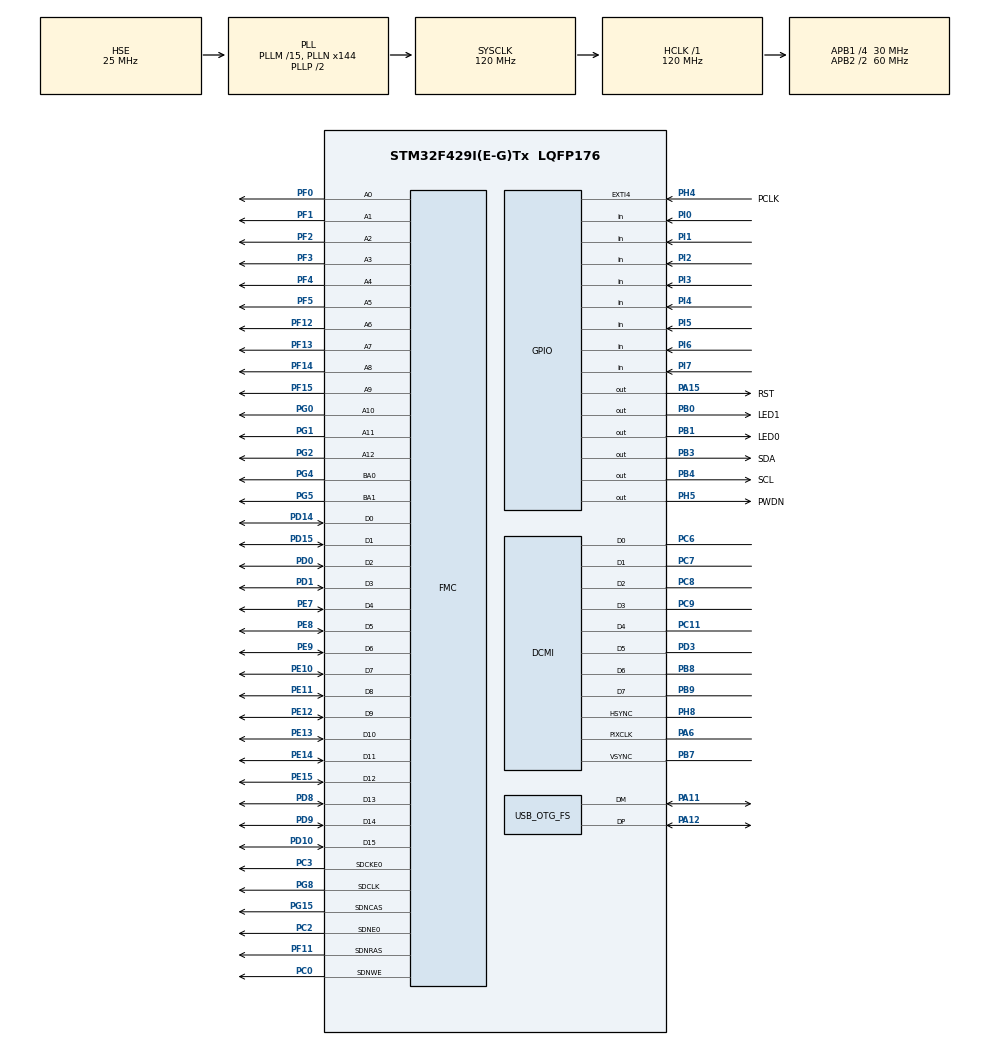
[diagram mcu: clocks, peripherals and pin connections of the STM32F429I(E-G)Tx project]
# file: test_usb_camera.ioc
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DCMI.PCKPolarity=DCMI_PCKPOLARITY_RISING
Dma.DCMI.0.Direction=DMA_PERIPH_TO_MEMORY
Dma.DCMI.0.FIFOMode=DMA_FIFOMODE_ENABLE
Dma.DCMI.0.FIFOThreshold=DMA_FIFO_THRESHOLD_HALFFULL
Dma.DCMI.0.Instance=DMA2_Stream1
Dma.DCMI.0.MemBurst=DMA_MBURST_SINGLE
Dma.DCMI.0.MemDataAlignment=DMA_MDATAALIGN_WORD
Dma.DCMI.0.MemInc=DMA_MINC_ENABLE
Dma.DCMI.0.Mode=DMA_CIRCULAR
Dma.DCMI.0.PeriphBurst=DMA_PBURST_SINGLE
Dma.DCMI.0.PeriphDataAlignment=DMA_PDATAALIGN_WORD
Dma.DCMI.0.PeriphInc=DMA_PINC_DISABLE
Dma.DCMI.0.Priority=DMA_PRIORITY_HIGH
Dma.Request0=DCMI
FMC.CASLatency1=FMC_SDRAM_CAS_LATENCY_3
FMC.ColumnBitsNumber1=FMC_SDRAM_COLUMN_BITS_NUM_9
FMC.ExitSelfRefreshDelay1=8
FMC.LoadToActiveDelay1=2
FMC.RCDDelay1=2
FMC.RPDelay1=2
FMC.RPDelay2=2
FMC.ReadBurst1=FMC_SDRAM_RBURST_ENABLE
FMC.ReadBurst2=FMC_SDRAM_RBURST_ENABLE
FMC.ReadPipeDelay1=FMC_SDRAM_RPIPE_DELAY_1
FMC.ReadPipeDelay2=FMC_SDRAM_RPIPE_DELAY_1
FMC.RowCycleDelay1=6
FMC.RowCycleDelay2=6
FMC.SDClockPeriod1=FMC_SDRAM_CLOCK_PERIOD_2
FMC.SDClockPeriod2=FMC_SDRAM_CLOCK_PERIOD_2
FMC.SelfRefreshTime1=6
FMC.WriteRecoveryTime1=4
Mcu.Family=STM32F4
Mcu.Name=STM32F429I(E-G)Tx
Mcu.Package=LQFP176
NVIC.DCMI_IRQn=true\:0\:0\:false\:false\:true\:true\:true
NVIC.DMA2_Stream1_IRQn=true\:0\:0\:false\:false\:true\:false\:true
NVIC.EXTI4_IRQn=true\:0\:0\:false\:false\:true\:true\:true
NVIC.OTG_FS_IRQn=true\:0\:0\:false\:false\:true\:false\:true
NVIC.PriorityGroup=NVIC_PRIORITYGROUP_4
PA11.Mode=Device_Only
PA11.Signal=USB_OTG_FS_DM
PA12.Mode=Device_Only
PA12.Signal=USB_OTG_FS_DP
PA15.GPIO_Label=RST
PA15.GPIO_PuPd=GPIO_PULLUP
PA15.GPIO_Speed=GPIO_SPEED_FREQ_VERY_HIGH
PA15.Signal=GPIO_Output
PA6.GPIO_PuPd=GPIO_PULLUP
PA6.GPIO_Speed=GPIO_SPEED_FREQ_VERY_HIGH
PA6.Mode=Slave_8_bits_External_Synchro
PA6.Signal=DCMI_PIXCLK
PB0.GPIO_Label=LED1
PB0.GPIO_PuPd=GPIO_PULLUP
PB0.GPIO_Speed=GPIO_SPEED_FREQ_VERY_HIGH
PB0.PinState=GPIO_PIN_SET
PB0.Signal=GPIO_Output
PB1.GPIO_Label=LED0
PB1.GPIO_PuPd=GPIO_PULLUP
PB1.GPIO_Speed=GPIO_SPEED_FREQ_VERY_HIGH
PB1.PinState=GPIO_PIN_SET
PB1.Signal=GPIO_Output
PB3.GPIO_Label=SDA
PB3.GPIO_ModeDefaultOutputPP=GPIO_MODE_OUTPUT_PP
PB3.GPIO_PuPd=GPIO_PULLUP
PB3.GPIO_Speed=GPIO_SPEED_FREQ_HIGH
PB3.Signal=GPIO_Output
PB4.GPIO_Label=SCL
PB4.GPIO_ModeDefaultOutputPP=GPIO_MODE_OUTPUT_PP
PB4.GPIO_PuPd=GPIO_PULLUP
PB4.GPIO_Speed=GPIO_SPEED_FREQ_HIGH
PB4.Signal=GPIO_Output
PB7.GPIO_PuPd=GPIO_PULLUP
PB7.GPIO_Speed=GPIO_SPEED_FREQ_VERY_HIGH
PB7.Mode=Slave_8_bits_External_Synchro
PB7.Signal=DCMI_VSYNC
PB8.GPIO_PuPd=GPIO_PULLUP
PB8.GPIO_Speed=GPIO_SPEED_FREQ_VERY_HIGH
PB8.Mode=Slave_8_bits_External_Synchro
PB8.Signal=DCMI_D6
PB9.GPIO_PuPd=GPIO_PULLUP
PB9.GPIO_Speed=GPIO_SPEED_FREQ_VERY_HIGH
PB9.Mode=Slave_8_bits_External_Synchro
PB9.Signal=DCMI_D7
PC0.Signal=FMC_SDNWE
PC11.GPIO_PuPd=GPIO_PULLUP
PC11.GPIO_Speed=GPIO_SPEED_FREQ_VERY_HIGH
PC11.Mode=Slave_8_bits_External_Synchro
PC11.Signal=DCMI_D4
PC2.Mode=SdramChipSelect1_1
PC2.Signal=FMC_SDNE0
PC3.Mode=SdramChipSelect1_1
PC3.Signal=FMC_SDCKE0
PC6.GPIO_PuPd=GPIO_PULLUP
PC6.GPIO_Speed=GPIO_SPEED_FREQ_VERY_HIGH
PC6.Mode=Slave_8_bits_External_Synchro
PC6.Signal=DCMI_D0
PC7.GPIO_PuPd=GPIO_PULLUP
PC7.GPIO_Speed=GPIO_SPEED_FREQ_VERY_HIGH
PC7.Mode=Slave_8_bits_External_Synchro
PC7.Signal=DCMI_D1
PC8.GPIO_PuPd=GPIO_PULLUP
PC8.GPIO_Speed=GPIO_SPEED_FREQ_VERY_HIGH
PC8.Mode=Slave_8_bits_External_Synchro
PC8.Signal=DCMI_D2
PC9.GPIO_PuPd=GPIO_PULLUP
PC9.GPIO_Speed=GPIO_SPEED_FREQ_VERY_HIGH
PC9.Mode=Slave_8_bits_External_Synchro
PC9.Signal=DCMI_D3
PD0.Signal=FMC_D2_DA2
PD1.Signal=FMC_D3_DA3
PD10.Signal=FMC_D15_DA15
PD14.Signal=FMC_D0_DA0
PD15.Signal=FMC_D1_DA1
PD3.GPIO_PuPd=GPIO_PULLUP
PD3.GPIO_Speed=GPIO_SPEED_FREQ_VERY_HIGH
PD3.Mode=Slave_8_bits_External_Synchro
PD3.Signal=DCMI_D5
PD8.Signal=FMC_D13_DA13
PD9.Signal=FMC_D14_DA14
PE10.Signal=FMC_D7_DA7
PE11.Signal=FMC_D8_DA8
PE12.Signal=FMC_D9_DA9
PE13.Signal=FMC_D10_DA10
PE14.Signal=FMC_D11_DA11
PE15.Signal=FMC_D12_DA12
PE7.Signal=FMC_D4_DA4
PE8.Signal=FMC_D5_DA5
PE9.Signal=FMC_D6_DA6
PF0.Signal=FMC_A0
PF1.Signal=FMC_A1
PF11.Signal=FMC_SDNRAS
PF12.Signal=FMC_A6
PF13.Signal=FMC_A7
PF14.Signal=FMC_A8
PF15.Signal=FMC_A9
PF2.Signal=FMC_A2
PF3.Signal=FMC_A3
PF4.Signal=FMC_A4
PF5.Signal=FMC_A5
PG0.Signal=FMC_A10
PG1.Signal=FMC_A11
PG15.Signal=FMC_SDNCAS
PG2.Signal=FMC_A12
PG4.Signal=FMC_A14_BA0
PG5.Signal=FMC_A15_BA1
PG8.Signal=FMC_SDCLK
PH0/OSC_IN.Mode=HSE-External-Oscillator
PH0/OSC_IN.Signal=RCC_OSC_IN
PH1/OSC_OUT.Mode=HSE-External-Oscillator
PH1/OSC_OUT.Signal=RCC_OSC_OUT
PH4.GPIO_Label=PCLK
PH4.GPIO_ModeDefaultEXTI=GPIO_MODE_IT_RISING
PH4.GPIO_PuPd=GPIO_PULLUP
PH4.Signal=GPXTI4
PH5.GPIO_Label=PWDN
PH5.GPIO_PuPd=GPIO_PULLUP
PH5.GPIO_Speed=GPIO_SPEED_FREQ_VERY_HIGH
PH5.Signal=GPIO_Output
PH8.GPIO_PuPd=GPIO_PULLUP
PH8.GPIO_Speed=GPIO_SPEED_FREQ_VERY_HIGH
PH8.Mode=Slave_8_bits_External_Synchro
PH8.Signal=DCMI_HSYNC
PI0.GPIO_PuPd=GPIO_PULLUP
PI0.Signal=GPIO_Input
PI1.GPIO_PuPd=GPIO_PULLUP
PI1.Signal=GPIO_Input
PI2.GPIO_PuPd=GPIO_PULLUP
PI2.Signal=GPIO_Input
PI3.GPIO_PuPd=GPIO_PULLUP
PI3.Signal=GPIO_Input
PI4.GPIO_PuPd=GPIO_PULLUP
PI4.Signal=GPIO_Input
PI5.GPIO_PuPd=GPIO_PULLUP
PI5.Signal=GPIO_Input
PI6.GPIO_PuPd=GPIO_PULLUP
PI6.Signal=GPIO_Input
PI7.GPIO_PuPd=GPIO_PULLUP
PI7.Signal=GPIO_Input
ProjectManager.HeapSize=0x600
ProjectManager.StackSize=0x400
ProjectManager.TargetToolchain=MDK-ARM V5
RCC.48MHZClocksFreq_Value=48000000
RCC.AHBFreq_Value=120000000
RCC.APB1CLKDivider=RCC_HCLK_DIV4
RCC.APB1Freq_Value=30000000
RCC.APB1TimFreq_Value=60000000
RCC.APB2CLKDivider=RCC_HCLK_DIV2
RCC.APB2Freq_Value=60000000
RCC.APB2TimFreq_Value=120000000
RCC.CortexFreq_Value=120000000
RCC.HCLKFreq_Value=120000000
RCC.HSE_VALUE=25000000
RCC.HSI_VALUE=16000000
RCC.LSE_VALUE=32768
RCC.PLLM=15
RCC.PLLN=144
RCC.PLLQ=5
RCC.SYSCLKFreq_VALUE=120000000
RCC.SYSCLKSource=RCC_SYSCLKSOURCE_PLLCLK
RCC.VCOOutputFreq_Value=240000000
SH.FMC_A0.0=FMC_A0,13b-sda1
SH.FMC_A1.0=FMC_A1,13b-sda1
SH.FMC_A10.0=FMC_A10,13b-sda1
SH.FMC_A11.0=FMC_A11,13b-sda1
SH.FMC_A12.0=FMC_A12,13b-sda1
SH.FMC_A14_BA0.0=FMC_BA0,FourSdramBanks1
SH.FMC_A15_BA1.0=FMC_BA1,FourSdramBanks1
SH.FMC_A2.0=FMC_A2,13b-sda1
SH.FMC_A3.0=FMC_A3,13b-sda1
SH.FMC_A4.0=FMC_A4,13b-sda1
SH.FMC_A5.0=FMC_A5,13b-sda1
SH.FMC_A6.0=FMC_A6,13b-sda1
SH.FMC_A7.0=FMC_A7,13b-sda1
SH.FMC_A8.0=FMC_A8,13b-sda1
SH.FMC_A9.0=FMC_A9,13b-sda1
SH.FMC_D0_DA0.0=FMC_D0,sd-16b-d1
SH.FMC_D10_DA10.0=FMC_D10,sd-16b-d1
SH.FMC_D11_DA11.0=FMC_D11,sd-16b-d1
SH.FMC_D12_DA12.0=FMC_D12,sd-16b-d1
SH.FMC_D13_DA13.0=FMC_D13,sd-16b-d1
SH.FMC_D14_DA14.0=FMC_D14,sd-16b-d1
SH.FMC_D15_DA15.0=FMC_D15,sd-16b-d1
SH.FMC_D1_DA1.0=FMC_D1,sd-16b-d1
SH.FMC_D2_DA2.0=FMC_D2,sd-16b-d1
SH.FMC_D3_DA3.0=FMC_D3,sd-16b-d1
SH.FMC_D4_DA4.0=FMC_D4,sd-16b-d1
SH.FMC_D5_DA5.0=FMC_D5,sd-16b-d1
SH.FMC_D6_DA6.0=FMC_D6,sd-16b-d1
SH.FMC_D7_DA7.0=FMC_D7,sd-16b-d1
SH.FMC_D8_DA8.0=FMC_D8,sd-16b-d1
SH.FMC_D9_DA9.0=FMC_D9,sd-16b-d1
SH.FMC_SDCLK.0=FMC_SDCLK,13b-sda1
SH.FMC_SDNCAS.0=FMC_SDNCAS,13b-sda1
SH.FMC_SDNRAS.0=FMC_SDNRAS,13b-sda1
SH.FMC_SDNWE.0=FMC_SDNWE,13b-sda1
USB_DEVICE.CLASS_NAME_FS=CDC
USB_DEVICE.VirtualMode-CDC_FS=Cdc
USB_DEVICE.VirtualModeFS=Cdc_FS
USB_OTG_FS.VirtualMode=Device_Only
VP_USB_DEVICE_VS_USB_DEVICE_CDC_FS.Mode=CDC_FS
board=custom

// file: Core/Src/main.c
/* USER CODE BEGIN Header */
/**
  ******************************************************************************
  * @file           : main.c
  * @brief          : Main program body
  ******************************************************************************
  * @attention
  *
  * <h2><center>&copy; Copyright (c) 2021 STMicroelectronics.
  * All rights reserved.</center></h2>
  *
  * This software component is licensed by ST under Ultimate Liberty license
  * SLA0044, the "License"; You may not use this file except in compliance with
  * the License. You may obtain a copy of the License at:
  *                             www.st.com/SLA0044
  *
  ******************************************************************************
  */
/* USER CODE END Header */
#include "main.h"
#include "dcmi.h"
#include "dma.h"
#include "usb_device.h"
#include "gpio.h"
#include "fmc.h"

/* USER CODE BEGIN Includes */
#include "usbd_cdc_if.h"
#include "hardware.h"
//#include "sdram.h"
#include "usb_app.h"
/* USER CODE END Includes */

void SystemClock_Config(void);

/* USER CODE BEGIN 0 */

#define BUFFER_SIZE 2*1024
#define DATA_SIZE 30*1024

uint32_t jpeg_data[DATA_SIZE]__attribute__((at(0XC0000000+1280*800*2)));
uint32_t jpeg_buffer[2][BUFFER_SIZE];
uint32_t jpeg_data_len = 0;
uint8_t jpeg_process_state = 0;
uint8_t current_buffer = 0;
uint8_t buf[4];

void save_buffer(uint8_t buffer_num)
{
	uint32_t *p = jpeg_data + jpeg_data_len;
	for(uint32_t i=0; i<BUFFER_SIZE; i++)
	{
		p[i] = jpeg_buffer[buffer_num][i];
	}
	jpeg_data_len = jpeg_data_len+BUFFER_SIZE;
}

void data_process()
{
	if(jpeg_process_state == 0)
	{
		save_buffer(current_buffer);
		jpeg_process_state = 1;
	}
	else if(jpeg_process_state == 2)
	{
		jpeg_process_state = 0;
		jpeg_data_len = 0;
	}
}

//void HAL_TIM_IC_CaptureCallback(TIM_HandleTypeDef *htim)
//{
//	if(jpeg_process_state == 0)
//	{
//		save_buffer(1);
//	}
//	current_buffer = 0;
//}

//void HAL_TIM_IC_CaptureHalfCpltCallback(TIM_HandleTypeDef *htim)
//{
//	if(jpeg_process_state == 0)
//	{
//		save_buffer(0);
//	}
//	current_buffer = 1;
//}

//void HAL_GPIO_EXTI_Callback(uint16_t GPIO_Pin)
//{
//	if(GPIO_Pin == GPIO_PIN_4)
//	{
//		if(jpeg_process_state)
//		{
//			jpeg_data[jpeg_data_len++] = GPIOI->IDR;
//		}
//	}
//	else if(GPIO_Pin == GPIO_PIN_7)
//	{
//		data_process();
//	}
//}

void HAL_DCMI_VsyncEventCallback(DCMI_HandleTypeDef *hdcmi)
{
	data_process();//jpeg数据处理
  __HAL_DCMI_ENABLE_IT(hdcmi, DCMI_FLAG_VSYNCRI);
}

void DCMI_DMAXferCplt(DMA_HandleTypeDef *hdma)
{
	if(jpeg_process_state==0)
	{
		HW_LED_turn(&led0);
		save_buffer(0);
	}
	current_buffer = 1;
}

void DCMI_DMAXferM1Cplt(DMA_HandleTypeDef *hdma)
{
	if(jpeg_process_state==0)
	{
		HW_LED_turn(&led1);
		save_buffer(1);
	}
	current_buffer = 0;
}

void DCMI_DMAXferError(DMA_HandleTypeDef *hdma)
{
	UNUSED(hdma);
}

HAL_StatusTypeDef dcmi_start(DCMI_HandleTypeDef* hdcmi, uint32_t DCMI_Mode, uint32_t pData, uint32_t pData2, uint32_t Length)
{
  /* Process Locked */
  __HAL_LOCK(hdcmi);

  /* Lock the DCMI peripheral state */
  hdcmi->State = HAL_DCMI_STATE_BUSY;

  /* Enable DCMI by setting DCMIEN bit */
  __HAL_DCMI_ENABLE(hdcmi);

  /* Configure the DCMI Mode */
  hdcmi->Instance->CR &= ~(DCMI_CR_CM);
  hdcmi->Instance->CR |=  (uint32_t)(DCMI_Mode);

  hdcmi->XferCount = 0U;
  hdcmi->XferTransferNumber = 0U;

//	__HAL_UNLOCK(&hdma_dcmi);
	hdcmi->DMA_Handle->XferCpltCallback = DCMI_DMAXferCplt;
	hdcmi->DMA_Handle->XferM1CpltCallback = DCMI_DMAXferM1Cplt;
	hdcmi->DMA_Handle->XferErrorCallback = DCMI_DMAXferError;
	HAL_DMAEx_MultiBufferStart_IT(hdcmi->DMA_Handle, (uint32_t)&hdcmi->Instance->DR, (uint32_t)pData, (uint32_t)pData2, Length);

  /* Enable Capture */
  hdcmi->Instance->CR |= DCMI_CR_CAPTURE;

  /* Release Lock */
  __HAL_UNLOCK(hdcmi);
  return HAL_OK;
}

/* USER CODE END 0 */

int main(void)
{

  /* MCU Configuration--------------------------------------------------------*/

  /* Reset of all peripherals, Initializes the Flash interface and the Systick. */
  HAL_Init();

  /* Configure the system clock */
  SystemClock_Config();

  /* Initialize all configured peripherals */
  MX_GPIO_Init();
  MX_DMA_Init();
  MX_USB_DEVICE_Init();
  MX_DCMI_Init();
  MX_FMC_Init();
  /* USER CODE BEGIN 2 */

	// sdram
//	SDRAM_Init();

	// led
	led_init();
	HW_LED_set(&led0, HW_LED_OFF);
	HW_LED_set(&led1, HW_LED_OFF);
	delay_ms(1000);

	// ov5640
	ov5640_init();
 	HW_OV5640_set_rgb565(&ov5640);
////	OV5640_Focus_Init();
	HW_OV5640_set_jpeg(&ov5640);
////	OV5640_Light_Mode(0);	//自动模式
////	OV5640_Color_Saturation(3);//色彩饱和度0
////	OV5640_Brightness(4);	//亮度0
////	OV5640_Contrast(3);		//对比度0
////	OV5640_Sharpness(33);	//自动锐度
////	OV5640_Focus_Constant();//启动持续对焦
 	HW_OV5640_set_resolution(&ov5640, 4,0,320,240);//设置输出尺寸

  /* USER CODE END 2 */

  /* Infinite loop */
  /* USER CODE BEGIN WHILE */
//	jpeg_process_state = 2;
//  HAL_NVIC_EnableIRQ(EXTI4_IRQn);
//	HAL_TIM_IC_Start_DMA(&htim8, TIM_CHANNEL_1, (uint32_t*)jpeg_buffer, BUFFER_SIZE*2);
//	HAL_NVIC_EnableIRQ(EXTI9_5_IRQn);

//	HAL_DCMI_Start_DMA(&hdcmi, DCMI_MODE_CONTINUOUS, (uint32_t)jpeg_buffer, BUFFER_SIZE*2);
	dcmi_start(&hdcmi, DCMI_MODE_CONTINUOUS, (uint32_t)&jpeg_buffer[0], (uint32_t)&jpeg_buffer[1], BUFFER_SIZE);

	while (1)
  {
    /* USER CODE END WHILE */

    /* USER CODE BEGIN 3 */
		if(jpeg_process_state==1)
		{
			uint8_t *p = (uint8_t*)jpeg_data;
			uint8_t find_head = 0;
			uint32_t head_idx = 0;
			uint32_t jpeg_len = 0;
			if(jpeg_data_len)
			{
				for(uint32_t i = 0 ; i < jpeg_data_len*4-1; i++)
				{
					if(p[i]==0xff && p[i+1]==0xd8)
					{
						head_idx = i;
						find_head = 1;
					}
					else if(p[i]==0xff && p[i+1]==0xd9 && find_head)
					{
						jpeg_len = i+2-head_idx;
						break;
					}
				}
			}
			// if data correct transmit jpeg via usb
			if(jpeg_len)
			{
//				USB2PC((uint8_t*)jpeg_data+head_idx, jpeg_len);
				CDC_Transmit_FS((uint8_t*)jpeg_data + head_idx, jpeg_len);
			}
			// process finish;
			jpeg_process_state = 2;
		}
  }
  /* USER CODE END 3 */
}

void SystemClock_Config(void)
{
  RCC_OscInitTypeDef RCC_OscInitStruct = {0};
  RCC_ClkInitTypeDef RCC_ClkInitStruct = {0};

  /** Configure the main internal regulator output voltage
  */
  __HAL_RCC_PWR_CLK_ENABLE();
  __HAL_PWR_VOLTAGESCALING_CONFIG(PWR_REGULATOR_VOLTAGE_SCALE3);
  /** Initializes the RCC Oscillators according to the specified parameters
  * in the RCC_OscInitTypeDef structure.
  */
  RCC_OscInitStruct.OscillatorType = RCC_OSCILLATORTYPE_HSE;
  RCC_OscInitStruct.HSEState = RCC_HSE_ON;
  RCC_OscInitStruct.PLL.PLLState = RCC_PLL_ON;
  RCC_OscInitStruct.PLL.PLLSource = RCC_PLLSOURCE_HSE;
  RCC_OscInitStruct.PLL.PLLM = 15;
  RCC_OscInitStruct.PLL.PLLN = 144;
  RCC_OscInitStruct.PLL.PLLP = RCC_PLLP_DIV2;
  RCC_OscInitStruct.PLL.PLLQ = 5;
  if (HAL_RCC_OscConfig(&RCC_OscInitStruct) != HAL_OK)
  {
    Error_Handler();
  }
  /** Initializes the CPU, AHB and APB buses clocks
  */
  RCC_ClkInitStruct.ClockType = RCC_CLOCKTYPE_HCLK|RCC_CLOCKTYPE_SYSCLK
                              |RCC_CLOCKTYPE_PCLK1|RCC_CLOCKTYPE_PCLK2;
  RCC_ClkInitStruct.SYSCLKSource = RCC_SYSCLKSOURCE_PLLCLK;
  RCC_ClkInitStruct.AHBCLKDivider = RCC_SYSCLK_DIV1;
  RCC_ClkInitStruct.APB1CLKDivider = RCC_HCLK_DIV4;
  RCC_ClkInitStruct.APB2CLKDivider = RCC_HCLK_DIV2;

  if (HAL_RCC_ClockConfig(&RCC_ClkInitStruct, FLASH_LATENCY_3) != HAL_OK)
  {
    Error_Handler();
  }
}

void Error_Handler(void)
{
  __disable_irq();
  while (1)
  {
  }
}

/************************ (C) COPYRIGHT STMicroelectronics *****END OF FILE****/
